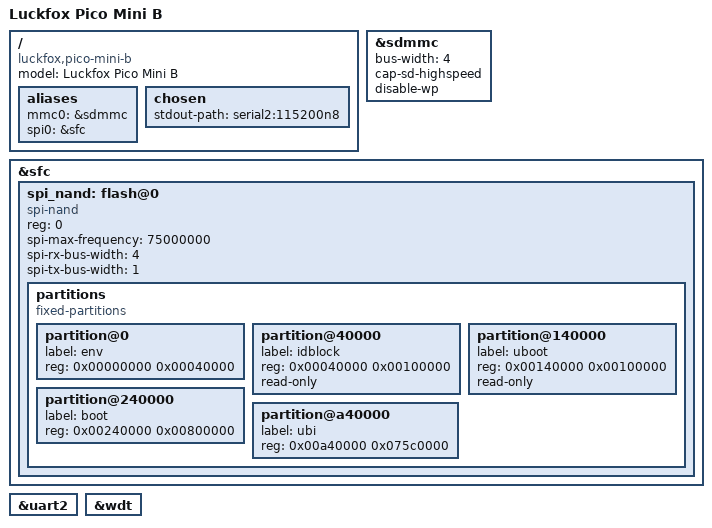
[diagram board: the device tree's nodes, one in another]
// SPDX-License-Identifier: (GPL-2.0+ OR MIT)
/*
 * Copyright (c) 2023 Luckfox Electronics Co., Ltd
 */

/dts-v1/;

#include "rv1103.dtsi"

/ {
	model = "Luckfox Pico Mini B";
	compatible = "luckfox,pico-mini-b", "rockchip,rv1103";

	aliases {
		mmc0 = &sdmmc;
		spi0 = &sfc;
	};

	chosen {
		stdout-path = "serial2:115200n8";
	};
};

&sdmmc {
	bus-width = <4>;
	cap-sd-highspeed;
	disable-wp;
	status = "okay";
};

&sfc {
	status = "okay";

	spi_nand: flash@0 {
		compatible = "spi-nand";
		reg = <0>;
		bootph-pre-ram;
		bootph-some-ram;
		spi-max-frequency = <75000000>;
		spi-rx-bus-width = <4>;
		spi-tx-bus-width = <1>;

		partitions {
			compatible = "fixed-partitions";
			#address-cells = <1>;
			#size-cells = <1>;

			partition@0 {
				label = "env";
				reg = <0x00000000 0x00040000>;
			};

			partition@40000 {
				label = "idblock";
				reg = <0x00040000 0x00100000>;
				read-only;
			};

			partition@140000 {
				label = "uboot";
				reg = <0x00140000 0x00100000>;
				read-only;
			};

			partition@240000 {
				label = "boot";
				reg = <0x00240000 0x00800000>;
			};

			partition@a40000 {
				label = "ubi";
				reg = <0x00a40000 0x075c0000>;
			};
		};
	};
};

&uart2 {
	bootph-all;
	status = "okay";
};

&wdt {
	status = "okay";
};
